# S6E1A1 register map
File version: 1.2
CPU: 
Registers are 32-bit, read-write, reset 0x0 unless marked. A register's access mark holds for its fields unless they carry their own. Offsets are from the block's base; [hi:lo] are bit positions.

## BTIOSEL03 — Base Timer I/O Select
Base 0x40025100
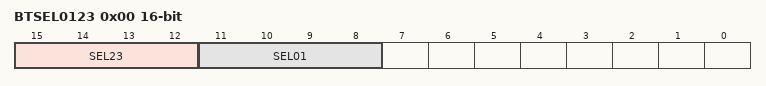
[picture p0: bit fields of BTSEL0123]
0x00 BTSEL0123 16-bit — I/O Select Register
  [15:12] SEL23 — I/O select bits for Ch.2/Ch.3
  [11:8] SEL01 — I/O select bits for Ch.0/Ch.1

## SBSSR — Software-based Simultaneous Startup Register
Base 0x40025F00
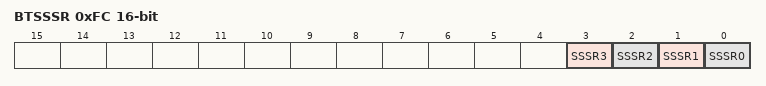
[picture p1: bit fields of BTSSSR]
0xFC BTSSSR 16-bit wo — Software-based Simultaneous Startup Register
  [3] SSSR3 — Software-based simultaneous startup bit of Ch.3
  [2] SSSR2 — Software-based simultaneous startup bit of Ch.2
  [1] SSSR1 — Software-based simultaneous startup bit of Ch.1
  [0] SSSR0 — Software-based simultaneous startup bit of Ch.0

## QPRC0 — Quadrature Position/Revolution Counter 0
Base 0x40026000
0x00 QPCR 16-bit — QPRC Position Count Register
0x04 QRCR 16-bit — QPRC Revolution Count Register
0x08 QPCCR 16-bit — QPRC Position Counter Compare Register
0x0C QPRCR 16-bit — QPRC Position and Revolution Counter Compare Register
0x10 QMPR 16-bit reset 0xFFFF — QPRC Maximum Position Register
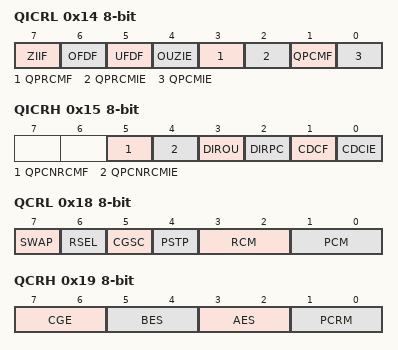
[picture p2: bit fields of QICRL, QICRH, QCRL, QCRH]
0x14 QICRL 8-bit — Low-Order Bytes of QPRC Interrupt Control Register
  [7] ZIIF — Zero index interrupt request flag bit
  [6] OFDF — Overflow interrupt request flag bit
  [5] UFDF — Underflow interrupt request flag bit
  [4] OUZIE — Overflow@ underflow@ or zero index interrupt enable bit
  [3] QPRCMF — PC and RC match interrupt request flag bit
  [2] QPRCMIE — PC and RC match interrupt enable bit
  [1] QPCMF — PC match interrupt request flag bit
  [0] QPCMIE — PC match interrupt enable bit
0x15 QICRH 8-bit — High-Order Bytes of QPRC Interrupt Control Register
  [5] QPCNRCMF — PC match and RC match interrupt request flag bit
  [4] QPCNRCMIE — PC match and RC match interrupt enable bit
  [3] DIROU ro — Last position counter flow direction bit
  [2] DIRPC ro — Last position counter direction bit
  [1] CDCF — Count inversion interrupt request flag bit
  [0] CDCIE — Count inversion interrupt enable bit
0x18 QCRL 8-bit — Low-Order Bytes of QPRC Control Register
  [7] SWAP — Swap bit
  [6] RSEL — Register function selection bit
  [5] CGSC — Count clear or gate selection bit
  [4] PSTP — Position counter stop bit
  [3:2] RCM — Revolution counter mode bits
  [1:0] PCM — Position counter mode bits
0x19 QCRH 8-bit — High-Order Bytes of QPRC Control Register
  [7:6] CGE — Detection edge selection bits
  [5:4] BES — BIN detection edge selection bits
  [3:2] AES — AIN detection edge selection bits
  [1:0] PCRM — Position counter reset mask bits
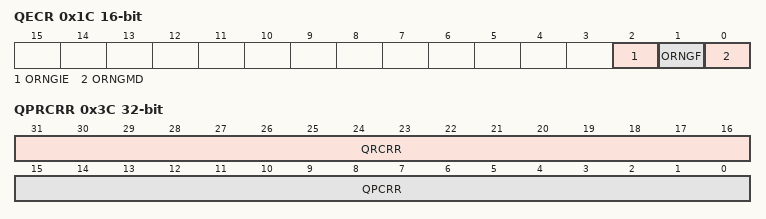
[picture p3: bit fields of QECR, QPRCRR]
0x1C QECR 16-bit — QPRC Extension Control Register
  [2] ORNGIE — Outrange interrupt enable bit
  [1] ORNGF — Outrange interrupt request flag bit
  [0] ORNGMD — Outrange mode selection bit
0x3C QPRCRR ro — Quad Counter Position Rotation Count Register
  [31:16] QRCRR — Quad counter rotation count display bit
  [15:0] QPCRR — Quad counter position count display bit

## QPRC0_NF — Quadrature Position/Revolution Counter 0 Noise Filter
Base 0x40026100
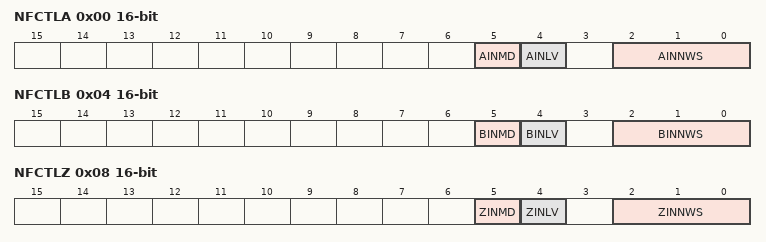
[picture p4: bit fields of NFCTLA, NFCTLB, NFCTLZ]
0x00 NFCTLA 16-bit — AIN Noise Control Register
  [5] AINMD — Mask bit
  [4] AINLV — Input invert bit
  [2:0] AINNWS — Noise filter width select bits
0x04 NFCTLB 16-bit — BIN Noise Control Register
  [5] BINMD — Mask bit
  [4] BINLV — Input invert bit
  [2:0] BINNWS — Noise filter width select bits
0x08 NFCTLZ 16-bit — ZIN Noise Control Register
  [5] ZINMD — Mask bit
  [4] ZINLV — Input invert bit
  [2:0] ZINNWS — Noise filter width select bits

## CRTRIM — CR Trimming Registers
Base 0x4002E000
0x00 MCR_PSR 8-bit reset 0x1 — High-speed CR Oscillation Frequency Division Setup Register
  [2:0] CSR — High-speed CR oscillation frequency division ratio setting bits
0x04 MCR_FTRM 16-bit reset 0x1EF — High-speed CR Oscillation Frequency Trimming Register
  [9:0] TRD — Frequency trimming setup bits
0x08 MCR_TTRM 8-bit reset 0x10 — High-speed CR Oscillation Temperature Trimming Setup Register
  [4:0] TRT — Temperature trimming setup bits
0x0C MCR_RLR reset 0x1 — High-Speed CR Oscillation Register Write-Protect Register
  [31:0] TRMLCK — Register write-protect bits
